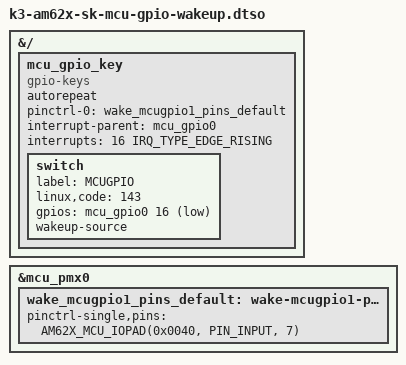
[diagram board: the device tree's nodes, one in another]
// SPDX-License-Identifier: GPL-2.0
/**
 * MCU GPIO 0_16 on the AM625-SK EVM can be used to wakeup system from deep sleep
 * with the help of this overlay
 *
 * Copyright (C) 2023 Texas Instruments Incorporated - http://www.ti.com/
 */

/dts-v1/;
/plugin/;

#include <dt-bindings/gpio/gpio.h>
#include <dt-bindings/interrupt-controller/irq.h>

#include "k3-pinctrl.h"

&{/} {
	mcu_gpio_key {
		compatible = "gpio-keys";
			autorepeat;
		pinctrl-names = "default";
		pinctrl-0 = <&wake_mcugpio1_pins_default>;
		interrupt-parent = <&mcu_gpio0>;
		interrupts = <16 IRQ_TYPE_EDGE_RISING>;
		switch {
			label = "MCUGPIO";
			linux,code = <143>;
			gpios = <&mcu_gpio0 16 GPIO_ACTIVE_LOW>;
			wakeup-source;
		};
	};
};

&mcu_pmx0 {
	wake_mcugpio1_pins_default: wake-mcugpio1-pins-default {
		pinctrl-single,pins = <
			AM62X_MCU_IOPAD(0x0040, PIN_INPUT, 7) /* (D6) MCU_MCAN1_RX.MCU_GPIO0_16 */
		>;
	};
};
